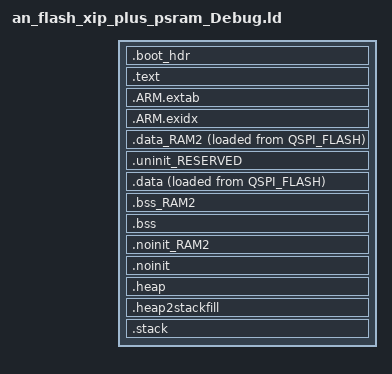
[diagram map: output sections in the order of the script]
/*
 * GENERATED FILE - DO NOT EDIT
 * Copyright 2008-2013 Code Red Technologies Ltd,
 * Copyright 2013-2024 NXP
 * Generated linker script file for RW612
 * Created from linkscript.ldt by FMCreateLinkLibraries
 * Using Freemarker v2.3.30
 * MCUXpresso IDE v11.9.0 [Build 2144] [2024-01-05] on Aug 12, 2024, 4:18:30 PM
 */

INCLUDE "an_flash_xip_plus_psram_Debug_library.ld"
INCLUDE "an_flash_xip_plus_psram_Debug_memory.ld"

ENTRY(ResetISR)

SECTIONS
{
     /* Offset .text by 0x1000 bytes, which whill be added by the image tool*/
    .boot_hdr : ALIGN(4)
    {
        FILL(0xFF)
        . = 0x400;
        __FLASH_BASE = .;
        KEEP(*(.flash_conf))
        . = 0x1000;
    } > QSPI_FLASH

    /* MAIN TEXT SECTION */
    .text : ALIGN(4)
    {
        FILL(0xff)
        __vectors_start__ = ABSOLUTE(.) ;
        KEEP(*(.isr_vector))
        /* Global Section Table */
        . = ALIGN(4) ;
        __section_table_start = .;
        __data_section_table = .;
        LONG(LOADADDR(.data));
        LONG(    ADDR(.data));
        LONG(  SIZEOF(.data));
        LONG(LOADADDR(.data_RAM2));
        LONG(    ADDR(.data_RAM2));
        LONG(  SIZEOF(.data_RAM2));
        __data_section_table_end = .;
        __bss_section_table = .;
        LONG(    ADDR(.bss));
        LONG(  SIZEOF(.bss));
        LONG(    ADDR(.bss_RAM2));
        LONG(  SIZEOF(.bss_RAM2));
        __bss_section_table_end = .;
        __section_table_end = . ;
        /* End of Global Section Table */

        *(.after_vectors*)


        *(EXCLUDE_FILE(*fsl_flexspi.o *fsl_clock.o *clock_config.o *fsl_reset.o *fsl_debug_console.o *fsl_cache.o) .text*)
       *(.rodata .rodata.* .constdata .constdata.*)
       . = ALIGN(4);
    } > QSPI_FLASH
    /*
     * for exception handling/unwind - some Newlib functions (in common
     * with C++ and STDC++) use this.
     */
    .ARM.extab : ALIGN(4)
    {
        *(.ARM.extab* .gnu.linkonce.armextab.*)
    } > QSPI_FLASH

    .ARM.exidx : ALIGN(4)
    {
        __exidx_start = .;
        *(.ARM.exidx* .gnu.linkonce.armexidx.*)
        __exidx_end = .;
    } > QSPI_FLASH
 
    _etext = .;
        
    /* DATA section for PSRAM */

    .data_RAM2 : ALIGN(4)
    {
        FILL(0xff)
        PROVIDE(__start_data_RAM2 = .) ;
        PROVIDE(__start_data_PSRAM = .) ;
        *(.ramfunc.$RAM2)
        *(.ramfunc.$PSRAM)
        *(.data.$RAM2)
        *(.data.$PSRAM)
        *(.data.$RAM2.*)
        *(.data.$PSRAM.*)
        . = ALIGN(4) ;
        PROVIDE(__end_data_RAM2 = .) ;
        PROVIDE(__end_data_PSRAM = .) ;
     } > PSRAM AT>QSPI_FLASH

    /* MAIN DATA SECTION */
    .uninit_RESERVED (NOLOAD) : ALIGN(4)
    {
        _start_uninit_RESERVED = .;
        KEEP(*(.bss.$RESERVED*))
       . = ALIGN(4) ;
        _end_uninit_RESERVED = .;
    } > SRAM AT> SRAM

    /* Main DATA section (SRAM) */
    .data : ALIGN(4)
    {
       FILL(0xff)
       _data = . ;
       PROVIDE(__start_data_RAM = .) ;
       PROVIDE(__start_data_SRAM = .) ;
       *(vtable)
       *(.ramfunc*)
       KEEP(*(CodeQuickAccess))
       KEEP(*(DataQuickAccess))
       *(RamFunction)

       *fsl_flexspi.o (.text*)
       *fsl_clock.o (.text*)
       *clock_config.o (.text*)
       *fsl_reset.o (.text*)
       *fsl_debug_console.o (.text*)
       *fsl_cache.o (.text*)
       *(.data*)
       . = ALIGN(4) ;
       _edata = . ;
       PROVIDE(__end_data_RAM = .) ;
       PROVIDE(__end_data_SRAM = .) ;
    } > SRAM AT>QSPI_FLASH

    /* BSS section for PSRAM */
    .bss_RAM2 (NOLOAD) : ALIGN(4)
    {
       PROVIDE(__start_bss_RAM2 = .) ;
       PROVIDE(__start_bss_PSRAM = .) ;
       *(.bss.$RAM2)
       *(.bss.$PSRAM)
       *(.bss.$RAM2.*)
       *(.bss.$PSRAM.*)
       . = ALIGN (. != 0 ? 4 : 1) ; /* avoid empty segment */
       PROVIDE(__end_bss_RAM2 = .) ;
       PROVIDE(__end_bss_PSRAM = .) ;
    } > PSRAM AT> PSRAM

    /* MAIN BSS SECTION */
    .bss (NOLOAD) : ALIGN(4)
    {
        _bss = .;
        PROVIDE(__start_bss_RAM = .) ;
        PROVIDE(__start_bss_SRAM = .) ;
        *(.bss*)
        *(COMMON)
        . = ALIGN(4) ;
        _ebss = .;
        PROVIDE(__end_bss_RAM = .) ;
        PROVIDE(__end_bss_SRAM = .) ;
        PROVIDE(end = .);
    } > SRAM AT> SRAM

    /* NOINIT section for PSRAM */
    .noinit_RAM2 (NOLOAD) : ALIGN(4)
    {
       PROVIDE(__start_noinit_RAM2 = .) ;
       PROVIDE(__start_noinit_PSRAM = .) ;
       *(.noinit.$RAM2)
       *(.noinit.$PSRAM)
       *(.noinit.$RAM2.*)
       *(.noinit.$PSRAM.*)
       . = ALIGN(4) ;
       PROVIDE(__end_noinit_RAM2 = .) ;
       PROVIDE(__end_noinit_PSRAM = .) ;
    } > PSRAM AT> PSRAM

    /* DEFAULT NOINIT SECTION */
    .noinit (NOLOAD): ALIGN(4)
    {
        _noinit = .;
        PROVIDE(__start_noinit_RAM = .) ;
        PROVIDE(__start_noinit_SRAM = .) ;
        *(.noinit*)
        . = ALIGN(4) ;
        _end_noinit = .;
        PROVIDE(__end_noinit_RAM = .) ;
        PROVIDE(__end_noinit_SRAM = .) ;
    } > SRAM AT> SRAM
    /* Reserve and place Heap within memory map */
    _HeapSize = 0x1000;
    .heap (NOLOAD) :  ALIGN(4)
    {
        _pvHeapStart = .;
        . += _HeapSize;
        . = ALIGN(4);
        _pvHeapLimit = .;
    } > SRAM

     _StackSize = 0x1000;
     /* Reserve space in memory for Stack */
    .heap2stackfill (NOLOAD) :
    {
        . += _StackSize;
    } > SRAM
    /* Locate actual Stack in memory map */
    .stack ORIGIN(SRAM) + LENGTH(SRAM) - _StackSize - 0 (NOLOAD) :  ALIGN(4)
    {
        _vStackBase = .;
        . = ALIGN(4);
        _vStackTop = . + _StackSize;
    } > SRAM

    /* Provide basic symbols giving location and size of main text
     * block, including initial values of RW data sections. Note that
     * these will need extending to give a complete picture with
     * complex images (e.g multiple Flash banks).
     */
    _image_start = LOADADDR(.text);
    _image_end = LOADADDR(.data) + SIZEOF(.data);
    _image_size = _image_end - _image_start;
}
